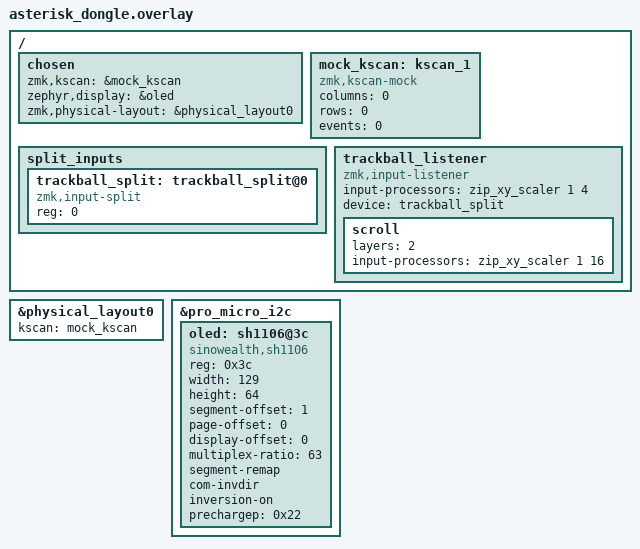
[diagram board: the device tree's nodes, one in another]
#include "asterisk.dtsi"

/ {
    chosen {
        zmk,kscan = &mock_kscan;
        zephyr,display = &oled;
        zmk,physical-layout = &physical_layout0;
    };

    mock_kscan: kscan_1 {
        compatible = "zmk,kscan-mock";
        columns = <0>;
        rows = <0>;
        events = <0>;
    };

};

&physical_layout0 {
        kscan = <&mock_kscan>;
};

&pro_micro_i2c {
    status = "okay";
    oled: sh1106@3c {
        compatible = "sinowealth,sh1106";
        reg = <0x3c>;
        width = <129>;
        height = <64>;
        segment-offset = <1>;
        page-offset = <0>;
        display-offset = <0>;
        multiplex-ratio = <63>;
        segment-remap;
        com-invdir;
        inversion-on;
        prechargep = <0x22>;
    };
}; 

/{
    split_inputs {
        #address-cells = <1>;
        #size-cells = <0>;

        trackball_split: trackball_split@0 {
            compatible = "zmk,input-split";
            reg = <0>;
        };
    };

      trackball_listener: trackball_listener {
        compatible = "zmk,input-listener";
        status = "okay";
        input-processors = <&zip_xy_scaler 1 4>;
        device = <&trackball_split>;

        scroll {
            layers = <2>;
            input-processors = <&zip_xy_scaler 1 16>;
        };
    };
};
 
